AUTOSAR XML (schema 00048)
package /VehicleProject
  system System
package /Cluster
  can cluster CAN00: baudrate=500000, protocol-name=CAN, can-fd-baudrate=500000  # CANFD364 | AUTOSAR series communication matrix (application + NM). Calibration/XCP is NOT part of this matrix; see CANFD364_XCP_Dev.dbc and configure Xcp PDU in DaVinci/EcuC only.
    can physical channel CHNL: comm-connectors=CN_CAN00
      frame msg_MotorStatus_oCAN00: id 0x511, from MyECU, frame-length=12, can-addressing-mode=STANDARD, can-frame-rx-behavior=ANY, can-frame-tx-behavior=CAN-FD  # MyECU TX motor status (Com). Cycle 5 ms, CAN FD. Signals align with RTE: MotorMode, tle9180_Ov_Fault, Id_Ref, Iq_Ref, Vbus, ElectricAngle. Observation only; mode/current commands via XCP RAM write, not Com Rx.
        pdu msg_MotorStatus_oCAN00: length=12, minimum-delay=0, transmission-mode-false-timing=cyclic-timing={time-offset=0, time-period=0.005}, transmission-mode-true-timing=cyclic-timing={time-offset=0, time-period=0.005}, unused-bit-pattern=0
          signal MotorMode_omsg_MotorStatus_oCAN00: start 0, 8 bit, little-endian, i-signal-type=PRIMITIVE, init-value=0, base-type=uint8, compu-method=CM_MotorMode, data-constr=DC_MotorMode, transfer-property=PENDING  # Aligned with MotorMode_Type in MotorMode.h (0..7).
          signal tle9180_Ov_Fault_omsg_MotorStatus_oCAN00: start 8, 1 bit, little-endian, i-signal-type=PRIMITIVE, init-value=0, base-type=boolean, compu-method=CM_tle9180_Ov_Fault, data-constr=DC_tle9180_Ov_Fault, transfer-property=PENDING
          signal Id_Ref_omsg_MotorStatus_oCAN00: start 16, 16 bit, little-endian, i-signal-type=PRIMITIVE, init-value=0, base-type=sint16, compu-method=CM_Id_Ref, data-constr=DC_Id_Ref, unit=U_A, transfer-property=PENDING  # Actual Id current reference after clamp [A].
          signal Iq_Ref_omsg_MotorStatus_oCAN00: start 32, 16 bit, little-endian, i-signal-type=PRIMITIVE, init-value=0, base-type=sint16, compu-method=CM_Iq_Ref, data-constr=DC_Iq_Ref, unit=U_A, transfer-property=PENDING  # Actual Iq current reference after clamp [A].
          signal Vbus_omsg_MotorStatus_oCAN00: start 48, 16 bit, little-endian, i-signal-type=PRIMITIVE, init-value=0, base-type=sint16, compu-method=CM_Vbus, data-constr=DC_Vbus, unit=U_V, transfer-property=PENDING
          signal ElectricAngle_omsg_MotorStatus_oCAN00: start 64, 16 bit, little-endian, i-signal-type=PRIMITIVE, init-value=0, base-type=sint16, compu-method=CM_ElectricAngle, data-constr=DC_ElectricAngle, unit=U_rad, transfer-property=PENDING
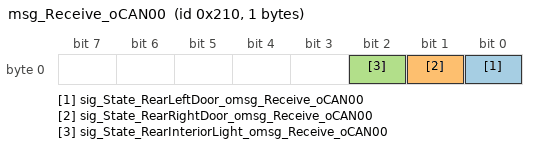
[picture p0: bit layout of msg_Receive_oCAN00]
      frame msg_Receive_oCAN00: id 0x210, to MyECU, frame-length=1, can-addressing-mode=STANDARD, can-frame-rx-behavior=ANY, can-frame-tx-behavior=CAN-20  # Legacy demo RX frame (kept for existing CanIf/Com). Prefer remove in later series cleanup if unused.
        pdu msg_Receive_oCAN00: length=1, minimum-delay=0, transmission-mode-false-timing=cyclic-timing={time-offset=0, time-period=0.1}, transmission-mode-true-timing=cyclic-timing={time-offset=0, time-period=0.1}, unused-bit-pattern=0
          signal sig_State_RearLeftDoor_omsg_Receive_oCAN00: start 0, 1 bit, little-endian, i-signal-type=PRIMITIVE, init-value=0, base-type=boolean, compu-method=CM_sig_State_RearLeftDoor, data-constr=DC_sig_State_RearLeftDoor, transfer-property=PENDING, to MyECU
          signal sig_State_RearRightDoor_omsg_Receive_oCAN00: start 1, 1 bit, little-endian, i-signal-type=PRIMITIVE, init-value=0, base-type=boolean, compu-method=CM_sig_State_RearRightDoor, data-constr=DC_sig_State_RearRightDoor, transfer-property=PENDING, to MyECU
          signal sig_State_RearInteriorLight_omsg_Receive_oCAN00: start 2, 1 bit, little-endian, i-signal-type=PRIMITIVE, init-value=0, base-type=boolean, compu-method=CM_sig_State_RearInteriorLight, data-constr=DC_sig_State_RearInteriorLight, transfer-property=PENDING, to MyECU
      frame msg_Transmit_oCAN00: id 0x200, from MyECU, frame-length=1, can-addressing-mode=STANDARD, can-frame-rx-behavior=ANY, can-frame-tx-behavior=CAN-20  # Legacy demo TX frame (kept for existing CanIf/Com). Prefer remove in later series cleanup if unused.
        pdu msg_Transmit_oCAN00: length=1, minimum-delay=0, transmission-mode-false-timing=cyclic-timing={time-offset=0, time-period=0.1}, transmission-mode-true-timing=cyclic-timing={time-offset=0, time-period=0.1}, unused-bit-pattern=0
          signal sig_RearInteriorLight_omsg_Transmit_oCAN00: start 0, 1 bit, little-endian, i-signal-type=PRIMITIVE, init-value=0, base-type=boolean, compu-method=CM_sig_RearInteriorLight, data-constr=DC_sig_RearInteriorLight, transfer-property=PENDING
package /ECU
  ecu instance MyECU: associated-com-i-pdu-group=[MyECU_oCAN00_Rx, MyECU_oCAN00_Tx]
    can communication controller CT_CAN00
    can communication connector CN_CAN00: comm-controller=CT_CAN00
package /IPDUGroup
  i signal i pdu group MyECU_oCAN00_Rx: communication-direction=IN, i-signal-i-pdus=msg_Receive_oCAN00
  i signal i pdu group MyECU_oCAN00_Tx: communication-direction=OUT, i-signal-i-pdus=[msg_MotorStatus_oCAN00, msg_Transmit_oCAN00]
